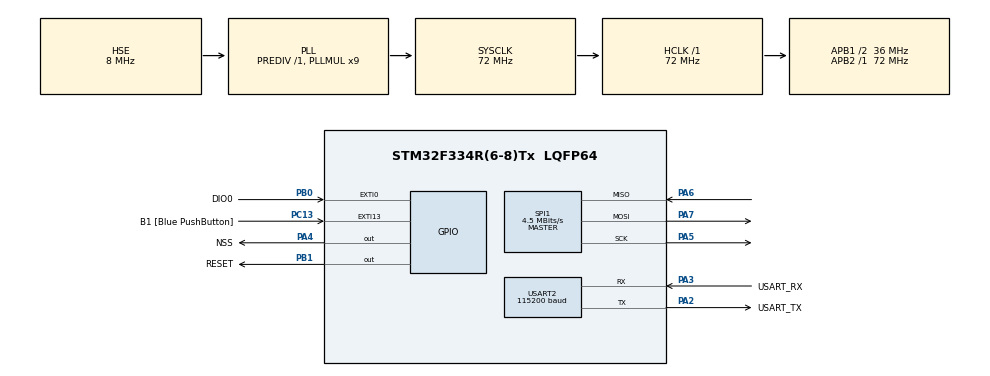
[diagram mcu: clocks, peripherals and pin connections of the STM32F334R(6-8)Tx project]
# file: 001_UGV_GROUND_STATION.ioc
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Dma.Request0=USART2_TX
Dma.USART2_TX.0.Direction=DMA_MEMORY_TO_PERIPH
Dma.USART2_TX.0.Instance=DMA1_Channel7
Dma.USART2_TX.0.MemDataAlignment=DMA_MDATAALIGN_BYTE
Dma.USART2_TX.0.MemInc=DMA_MINC_ENABLE
Dma.USART2_TX.0.Mode=DMA_NORMAL
Dma.USART2_TX.0.PeriphDataAlignment=DMA_PDATAALIGN_BYTE
Dma.USART2_TX.0.PeriphInc=DMA_PINC_DISABLE
Dma.USART2_TX.0.Priority=DMA_PRIORITY_MEDIUM
IWDG.Prescaler=IWDG_PRESCALER_16
IWDG.Reload=2000
IWDG.Window=4000
Mcu.Family=STM32F3
Mcu.Name=STM32F334R(6-8)Tx
Mcu.Package=LQFP64
NVIC.DMA1_Channel7_IRQn=true\:0\:0\:false\:false\:true\:false\:true\:true
NVIC.EXTI0_IRQn=true\:0\:0\:false\:false\:true\:true\:true\:true
NVIC.PriorityGroup=NVIC_PRIORITYGROUP_0
NVIC.USART2_IRQn=true\:0\:0\:false\:false\:true\:true\:true\:true
PA13.GPIO_Label=TMS
PA13.Mode=Serial_Wire
PA13.Signal=SYS_JTMS-SWDIO
PA14.GPIO_Label=TCK
PA14.Mode=Serial_Wire
PA14.Signal=SYS_JTCK-SWCLK
PA2.GPIO_Label=USART_TX
PA2.Mode=Asynchronous
PA2.Signal=USART2_TX
PA3.GPIO_Label=USART_RX
PA3.Mode=Asynchronous
PA3.Signal=USART2_RX
PA4.GPIO_Label=NSS
PA4.GPIO_Speed=GPIO_SPEED_FREQ_HIGH
PA4.PinState=GPIO_PIN_SET
PA4.Signal=GPIO_Output
PA5.Mode=Full_Duplex_Master
PA5.Signal=SPI1_SCK
PA6.Mode=Full_Duplex_Master
PA6.Signal=SPI1_MISO
PA7.Mode=Full_Duplex_Master
PA7.Signal=SPI1_MOSI
PB0.GPIO_Label=DIO0
PB0.Signal=GPXTI0
PB1.GPIO_Label=RESET
PB1.PinState=GPIO_PIN_SET
PB1.Signal=GPIO_Output
PB3.GPIO_Label=SWO
PB3.Signal=SYS_JTDO-TRACESWO
PC13.GPIO_Label=B1 [Blue PushButton]
PC13.GPIO_ModeDefaultEXTI=GPIO_MODE_IT_FALLING
PC13.Signal=GPXTI13
PC14\ /\ OSC32_IN.Mode=LSE-External-Oscillator
PC14\ /\ OSC32_IN.Signal=RCC_OSC32_IN
PC15\ /\ OSC32_OUT.GPIO_Label=RCC_OSC32_OUT
PC15\ /\ OSC32_OUT.Mode=LSE-External-Oscillator
PC15\ /\ OSC32_OUT.Signal=RCC_OSC32_OUT
PF0\ /\ OSC_IN.Mode=HSE-External-Clock-Source
PF0\ /\ OSC_IN.Signal=RCC_OSC_IN
PF1\ /\ OSC_OUT.Signal=RCC_OSC_OUT
ProjectManager.HeapSize=0x200
ProjectManager.StackSize=0x400
ProjectManager.TargetToolchain=STM32CubeIDE
RCC.AHBFreq_Value=72000000
RCC.APB1CLKDivider=RCC_HCLK_DIV2
RCC.APB1Freq_Value=36000000
RCC.APB1TimFreq_Value=72000000
RCC.APB2Freq_Value=72000000
RCC.APB2TimFreq_Value=72000000
RCC.CortexFreq_Value=72000000
RCC.FLatency-AdvancedSettings=FLASH_LATENCY_2
RCC.HCLKFreq_Value=72000000
RCC.HSE_VALUE=8000000
RCC.HSI_VALUE=8000000
RCC.PLLMUL=RCC_PLL_MUL9
RCC.PLLSourceVirtual=RCC_PLLSOURCE_HSE
RCC.SYSCLKFreq_VALUE=72000000
RCC.SYSCLKSourceVirtual=RCC_SYSCLKSOURCE_PLLCLK
SPI1.BaudRatePrescaler=SPI_BAUDRATEPRESCALER_16
SPI1.CalculateBaudRate=4.5 MBits/s
SPI1.DataSize=SPI_DATASIZE_8BIT
SPI1.Direction=SPI_DIRECTION_2LINES
SPI1.Mode=SPI_MODE_MASTER
SPI1.VirtualType=VM_MASTER
USART2.BaudRate=115200
USART2.VirtualMode-Asynchronous=VM_ASYNC
VP_IWDG_VS_IWDG.Mode=IWDG_Activate
board=NUCLEO-F334R8

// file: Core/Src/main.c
/* USER CODE BEGIN Header */
/**
  ******************************************************************************
  * @file           : main.c
  * @brief          : Main program body
  ******************************************************************************
  * @attention
  *
  * Copyright (c) 2024 STMicroelectronics.
  * All rights reserved.
  *
  * This software is licensed under terms that can be found in the LICENSE file
  * in the root directory of this software component.
  * If no LICENSE file comes with this software, it is provided AS-IS.
  *
  ******************************************************************************
  */
/* USER CODE END Header */
#include "main.h"
#include "dma.h"
#include "iwdg.h"
#include "spi.h"
#include "usart.h"
#include "gpio.h"

/* USER CODE BEGIN Includes */

#include "ugvMain.h"

/* USER CODE END Includes */

void SystemClock_Config(void);

int main(void)
{

  /* MCU Configuration--------------------------------------------------------*/

  /* Reset of all peripherals, Initializes the Flash interface and the Systick. */
  HAL_Init();

  /* Configure the system clock */
  SystemClock_Config();

  /* Initialize all configured peripherals */
  MX_GPIO_Init();
  MX_DMA_Init();
  MX_USART2_UART_Init();
  MX_SPI1_Init();
  MX_IWDG_Init();
  /* USER CODE BEGIN 2 */

//  init_PEC15_Table();
//
//  LoraData loraTxTry =
//  {
//		  .azimuth = 50,
//		  .latitudeDegree = 49,
//		  .latitudeMinute = 30,
//		  .latitudeSecond = 3.14f,
//		  .longitudeDegree = 55,
//		  .longitudeMinute = 20,
//		  .longitudeSecond = 3.14f,
//		  .numberOfSatellite = 4,
//		  .speed = 3.14f,
//		  .gpsState = WRONG_DATA,
//		  .ledState = FRONT_LED_ON,
//		  .crcLsb = 0,
//		  .crcMsb = 0,
//		  .carriage = '\r',
//		  .newline = '\n'
//  };

//  char dataBuffer[25];
//  uint32_t u32TempVar;
//
//  dataBuffer[0] = (loraTxTry.azimuth >> 0) & 0xFF;
//  dataBuffer[1] = (loraTxTry.azimuth >> 8) & 0xFF;
//  dataBuffer[2] = loraTxTry.latitudeDegree;
//  dataBuffer[3] = loraTxTry.latitudeMinute;
//  u32TempVar = *((uint32_t*)&loraTxTry.latitudeSecond);
//  dataBuffer[4] = (u32TempVar >> 0) & 0xFF;
//  dataBuffer[5] = (u32TempVar >> 8) & 0xFF;
//  dataBuffer[6] = (u32TempVar >> 16) & 0xFF;
//  dataBuffer[7] = (u32TempVar >> 24) & 0xFF;
//  dataBuffer[8] = loraTxTry.longitudeDegree;
//  dataBuffer[9] = loraTxTry.longitudeMinute;
//  u32TempVar = *((uint32_t*)&loraTxTry.longitudeSecond);
//  dataBuffer[10] = (u32TempVar >> 0) & 0xFF;
//  dataBuffer[11] = (u32TempVar >> 8) & 0xFF;
//  dataBuffer[12] = (u32TempVar >> 16) & 0xFF;
//  dataBuffer[13] = (u32TempVar >> 24) & 0xFF;
//  dataBuffer[14] = loraTxTry.numberOfSatellite;
//  u32TempVar = *((uint32_t*)&loraTxTry.speed);
//  dataBuffer[15] = (u32TempVar >> 0) & 0xFF;
//  dataBuffer[16] = (u32TempVar >> 8) & 0xFF;
//  dataBuffer[17] = (u32TempVar >> 16) & 0xFF;
//  dataBuffer[18] = (u32TempVar >> 24) & 0xFF;
//  dataBuffer[19] = loraTxTry.ledState;
//  dataBuffer[20] = loraTxTry.gpsState;
//
//  uint16_t pec = AE_pec15((uint8_t*)dataBuffer, 21);
//  dataBuffer[21] = (pec >> 0) & 0xFF;
//  dataBuffer[22] = (pec >> 8) & 0xFF;
//  dataBuffer[23] = loraTxTry.carriage;
//  dataBuffer[24] = loraTxTry.newline;

  /* USER CODE END 2 */

  /* Infinite loop */
  while (1)
  {

    /* USER CODE BEGIN 3 */

//	  uint32_t tick1 = HAL_GetTick();
//	  status = HAL_UART_Transmit(&huart2, (uint8_t*)dataBuffer, sizeof(dataBuffer), 10);
//
//	  uint32_t tick2 = HAL_GetTick();
//
//	  tickTime = tick2 - tick1;
//	  HAL_Delay(40);

	  ugvMain();
	  break;
  }
  /* USER CODE END 3 */
}

void SystemClock_Config(void)
{
  RCC_OscInitTypeDef RCC_OscInitStruct = {0};
  RCC_ClkInitTypeDef RCC_ClkInitStruct = {0};

  /** Initializes the RCC Oscillators according to the specified parameters
  * in the RCC_OscInitTypeDef structure.
  */
  RCC_OscInitStruct.OscillatorType = RCC_OSCILLATORTYPE_LSI|RCC_OSCILLATORTYPE_HSE;
  RCC_OscInitStruct.HSEState = RCC_HSE_BYPASS;
  RCC_OscInitStruct.HSEPredivValue = RCC_HSE_PREDIV_DIV1;
  RCC_OscInitStruct.HSIState = RCC_HSI_ON;
  RCC_OscInitStruct.LSIState = RCC_LSI_ON;
  RCC_OscInitStruct.PLL.PLLState = RCC_PLL_ON;
  RCC_OscInitStruct.PLL.PLLSource = RCC_PLLSOURCE_HSE;
  RCC_OscInitStruct.PLL.PLLMUL = RCC_PLL_MUL9;
  if (HAL_RCC_OscConfig(&RCC_OscInitStruct) != HAL_OK)
  {
    Error_Handler();
  }

  /** Initializes the CPU, AHB and APB buses clocks
  */
  RCC_ClkInitStruct.ClockType = RCC_CLOCKTYPE_HCLK|RCC_CLOCKTYPE_SYSCLK
                              |RCC_CLOCKTYPE_PCLK1|RCC_CLOCKTYPE_PCLK2;
  RCC_ClkInitStruct.SYSCLKSource = RCC_SYSCLKSOURCE_PLLCLK;
  RCC_ClkInitStruct.AHBCLKDivider = RCC_SYSCLK_DIV1;
  RCC_ClkInitStruct.APB1CLKDivider = RCC_HCLK_DIV2;
  RCC_ClkInitStruct.APB2CLKDivider = RCC_HCLK_DIV1;

  if (HAL_RCC_ClockConfig(&RCC_ClkInitStruct, FLASH_LATENCY_2) != HAL_OK)
  {
    Error_Handler();
  }
}

void Error_Handler(void)
{
  __disable_irq();
  while (1)
  {
  }
}
